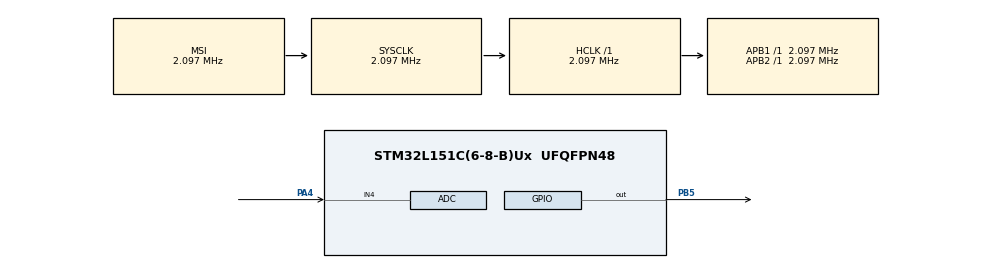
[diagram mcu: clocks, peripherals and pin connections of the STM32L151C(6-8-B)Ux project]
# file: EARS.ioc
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ADC.Channel-1\#ChannelRegularConversion=ADC_CHANNEL_4
ADC.NbrOfConversionFlag=1
ADC.Rank-1\#ChannelRegularConversion=1
ADC.SamplingTime-1\#ChannelRegularConversion=ADC_SAMPLETIME_4CYCLES
Mcu.Family=STM32L1
Mcu.Name=STM32L151C(6-8-B)Ux
Mcu.Package=UFQFPN48
NVIC.PriorityGroup=NVIC_PRIORITYGROUP_4
PA13.Mode=JTAG_5_pins
PA13.Signal=SYS_JTMS-SWDIO
PA14.Mode=JTAG_5_pins
PA14.Signal=SYS_JTCK-SWCLK
PA15.Mode=JTAG_5_pins
PA15.Signal=SYS_JTDI
PA4.Mode=IN4
PA4.Signal=ADC_IN4
PB3.Mode=JTAG_5_pins
PB3.Signal=SYS_JTDO-TRACESWO
PB4.Mode=JTAG_5_pins
PB4.Signal=SYS_JTRST
PB5.Signal=GPIO_Output
PC14-OSC32_IN.Mode=LSE-External-Oscillator
PC14-OSC32_IN.Signal=RCC_OSC32_IN
PC15-OSC32_OUT.Mode=LSE-External-Oscillator
PC15-OSC32_OUT.Signal=RCC_OSC32_OUT
PH0-OSC_IN.Mode=HSE-External-Oscillator
PH0-OSC_IN.Signal=RCC_OSC_IN
PH1-OSC_OUT.Mode=HSE-External-Oscillator
PH1-OSC_OUT.Signal=RCC_OSC_OUT
ProjectManager.HeapSize=0x200
ProjectManager.StackSize=0x400
ProjectManager.TargetToolchain=STM32CubeIDE
RCC.AHBFreq_Value=2097000
RCC.APB1Freq_Value=2097000
RCC.APB2Freq_Value=2097000
RCC.HSE_VALUE=8000000
RCC.HSI_VALUE=16000000
RCC.MSI_VALUE=2097000
RCC.SYSCLKFreq_VALUE=2097000
RCC.VCOOutputFreq_Value=48000000
board=custom

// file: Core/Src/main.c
/* USER CODE BEGIN Header */
/**
  ******************************************************************************
  * @file           : main.c
  * @brief          : Main program body
  ******************************************************************************
  * @attention
  *
  * <h2><center>&copy; Copyright (c) 2019 STMicroelectronics.
  * All rights reserved.</center></h2>
  *
  * This software component is licensed by ST under BSD 3-Clause license,
  * the "License"; You may not use this file except in compliance with the
  * License. You may obtain a copy of the License at:
  *                        opensource.org/licenses/BSD-3-Clause
  *
  ******************************************************************************
  */
/* USER CODE END Header */

#include "main.h"

/* USER CODE BEGIN PD */
#define PRESSURE_THRESHOLD 800
#define PRESSURE_DELAY 99
/* USER CODE END PD */

ADC_HandleTypeDef hadc;

/* USER CODE BEGIN PV */
uint16_t adcValue;
/* USER CODE END PV */

void SystemClock_Config(void);
static void MX_GPIO_Init(void);
static void MX_ADC_Init(void);

int main(void)
{

  /* MCU Configuration--------------------------------------------------------*/

  /* Reset of all peripherals, Initializes the Flash interface and the Systick. */
  HAL_Init();

  /* Configure the system clock */
  SystemClock_Config();

  /* Initialize all configured peripherals */
  MX_GPIO_Init();
  MX_ADC_Init();

  /* Infinite loop */
  while (1)
  {
	  HAL_ADC_Start(&hadc);
	  HAL_ADC_PollForConversion(&hadc, HAL_MAX_DELAY);
	  adcValue = HAL_ADC_GetValue(&hadc);
	  if(adcValue > PRESSURE_THRESHOLD)
	  {
		  HAL_GPIO_WritePin(GPIOB, GPIO_PIN_5, GPIO_PIN_SET);
		  HAL_Delay(PRESSURE_DELAY);
		  HAL_Delay(PRESSURE_DELAY);
		  HAL_Delay(PRESSURE_DELAY);
		  HAL_Delay(PRESSURE_DELAY);
	  }
	  HAL_GPIO_WritePin(GPIOB, GPIO_PIN_5, GPIO_PIN_RESET);
	  HAL_Delay(PRESSURE_DELAY);
	  HAL_Delay(PRESSURE_DELAY);
	  HAL_Delay(PRESSURE_DELAY);
	  HAL_Delay(PRESSURE_DELAY);
  }
}

void SystemClock_Config(void)
{
  RCC_OscInitTypeDef RCC_OscInitStruct = {0};
  RCC_ClkInitTypeDef RCC_ClkInitStruct = {0};

  /** Configure the main internal regulator output voltage
  */
  __HAL_PWR_VOLTAGESCALING_CONFIG(PWR_REGULATOR_VOLTAGE_SCALE1);
  /** Initializes the CPU, AHB and APB busses clocks
  */
  RCC_OscInitStruct.OscillatorType = RCC_OSCILLATORTYPE_HSI|RCC_OSCILLATORTYPE_MSI;
  RCC_OscInitStruct.HSIState = RCC_HSI_ON;
  RCC_OscInitStruct.HSICalibrationValue = RCC_HSICALIBRATION_DEFAULT;
  RCC_OscInitStruct.MSIState = RCC_MSI_ON;
  RCC_OscInitStruct.MSICalibrationValue = 0;
  RCC_OscInitStruct.MSIClockRange = RCC_MSIRANGE_5;
  RCC_OscInitStruct.PLL.PLLState = RCC_PLL_NONE;
  if (HAL_RCC_OscConfig(&RCC_OscInitStruct) != HAL_OK)
  {
    Error_Handler();
  }
  /** Initializes the CPU, AHB and APB busses clocks
  */
  RCC_ClkInitStruct.ClockType = RCC_CLOCKTYPE_HCLK|RCC_CLOCKTYPE_SYSCLK
                              |RCC_CLOCKTYPE_PCLK1|RCC_CLOCKTYPE_PCLK2;
  RCC_ClkInitStruct.SYSCLKSource = RCC_SYSCLKSOURCE_MSI;
  RCC_ClkInitStruct.AHBCLKDivider = RCC_SYSCLK_DIV1;
  RCC_ClkInitStruct.APB1CLKDivider = RCC_HCLK_DIV1;
  RCC_ClkInitStruct.APB2CLKDivider = RCC_HCLK_DIV1;

  if (HAL_RCC_ClockConfig(&RCC_ClkInitStruct, FLASH_LATENCY_0) != HAL_OK)
  {
    Error_Handler();
  }
}

static void MX_ADC_Init(void)
{

  ADC_ChannelConfTypeDef sConfig = {0};

  /** Configure the global features of the ADC (Clock, Resolution, Data Alignment and number of conversion)
  */
  hadc.Instance = ADC1;
  hadc.Init.ClockPrescaler = ADC_CLOCK_ASYNC_DIV1;
  hadc.Init.Resolution = ADC_RESOLUTION_12B;
  hadc.Init.DataAlign = ADC_DATAALIGN_RIGHT;
  hadc.Init.ScanConvMode = ADC_SCAN_DISABLE;
  hadc.Init.EOCSelection = ADC_EOC_SEQ_CONV;
  hadc.Init.LowPowerAutoWait = ADC_AUTOWAIT_DISABLE;
  hadc.Init.LowPowerAutoPowerOff = ADC_AUTOPOWEROFF_DISABLE;
  hadc.Init.ChannelsBank = ADC_CHANNELS_BANK_A;
  hadc.Init.ContinuousConvMode = DISABLE;
  hadc.Init.NbrOfConversion = 1;
  hadc.Init.DiscontinuousConvMode = DISABLE;
  hadc.Init.ExternalTrigConv = ADC_SOFTWARE_START;
  hadc.Init.ExternalTrigConvEdge = ADC_EXTERNALTRIGCONVEDGE_NONE;
  hadc.Init.DMAContinuousRequests = DISABLE;
  if (HAL_ADC_Init(&hadc) != HAL_OK)
  {
    Error_Handler();
  }
  /** Configure for the selected ADC regular channel its corresponding rank in the sequencer and its sample time.
  */
  sConfig.Channel = ADC_CHANNEL_4;
  sConfig.Rank = ADC_REGULAR_RANK_1;
  sConfig.SamplingTime = ADC_SAMPLETIME_4CYCLES;
  if (HAL_ADC_ConfigChannel(&hadc, &sConfig) != HAL_OK)
  {
    Error_Handler();
  }

}

static void MX_GPIO_Init(void)
{
  GPIO_InitTypeDef GPIO_InitStruct = {0};

  /* GPIO Ports Clock Enable */
  __HAL_RCC_GPIOC_CLK_ENABLE();
  __HAL_RCC_GPIOH_CLK_ENABLE();
  __HAL_RCC_GPIOA_CLK_ENABLE();
  __HAL_RCC_GPIOB_CLK_ENABLE();

  /*Configure GPIO pin Output Level */
  HAL_GPIO_WritePin(GPIOB, GPIO_PIN_5, GPIO_PIN_RESET);

  /*Configure GPIO pin : PB5 */
  GPIO_InitStruct.Pin = GPIO_PIN_5;
  GPIO_InitStruct.Mode = GPIO_MODE_OUTPUT_PP;
  GPIO_InitStruct.Pull = GPIO_NOPULL;
  GPIO_InitStruct.Speed = GPIO_SPEED_FREQ_LOW;
  HAL_GPIO_Init(GPIOB, &GPIO_InitStruct);

}

void Error_Handler(void)
{
}

/************************ (C) COPYRIGHT STMicroelectronics *****END OF FILE****/
